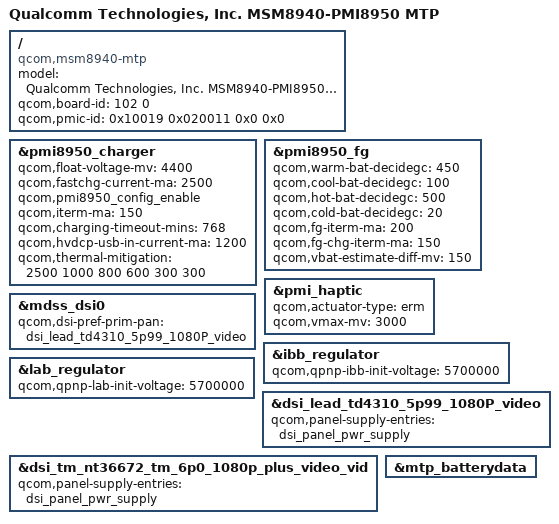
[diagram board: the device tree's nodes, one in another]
/*
 * Copyright (c) 2016, The Linux Foundation. All rights reserved.
 *
 * This program is free software; you can redistribute it and/or modify
 * it under the terms of the GNU General Public License version 2 and
 * only version 2 as published by the Free Software Foundation.
 *
 * This program is distributed in the hope that it will be useful,
 * but WITHOUT ANY WARRANTY; without even the implied warranty of
 * MERCHANTABILITY or FITNESS FOR A PARTICULAR PURPOSE.  See the
 * GNU General Public License for more details.
 */

/dts-v1/;

#include "msm8940.dtsi"
#include "msm8940-pmi8950-mtp.dtsi"
#include "zte-msm8940-pmi8950-maxxl2.dtsi"
#include "touch-key-backlight-maxx12.dtsi"
#include "msm8940-camera-sensor-zte-maxxl2.dtsi"

#include "dsi-panel-zte-lead-td4310-5p99-1080p-video.dtsi"
#include "dsi-panel-zte-tm-nt36672-tm-6p0-1080p-plus-video.dtsi"
/ {
	model = "Qualcomm Technologies, Inc. MSM8940-PMI8950 MTP";
	compatible = "qcom,msm8940-mtp", "qcom,msm8940", "qcom,mtp";
	qcom,board-id= <102 0>;
	qcom,pmic-id = <0x10019 0x020011 0x0 0x0>;
};

&pmi8950_charger {
	qcom,float-voltage-mv = <4400>;
	qcom,fastchg-current-ma = <2500>;
	qcom,pmi8950_config_enable;
	qcom,iterm-ma = <150>;
	qcom,charging-timeout-mins = <768>;
	qcom,hvdcp-usb-in-current-ma = <1200>;
	qcom,thermal-mitigation = <2500 1000 800 600 300 300>;
};
&pmi8950_fg{
	qcom,warm-bat-decidegc = <450>;
	qcom,cool-bat-decidegc = <100>;
	qcom,hot-bat-decidegc = <500>;
	qcom,cold-bat-decidegc = <20>;
	qcom,fg-iterm-ma = <200>;
	qcom,fg-chg-iterm-ma = <150>;
	qcom,vbat-estimate-diff-mv = <150>;
};
&pmi_haptic{
	qcom,actuator-type = "erm";
	qcom,vmax-mv = <3000>;
};
&mdss_dsi0 {
	qcom,dsi-pref-prim-pan = <&dsi_lead_td4310_5p99_1080P_video>;
};

&ibb_regulator {
	qcom,qpnp-ibb-init-voltage = <5700000>;
};

&lab_regulator {
	qcom,qpnp-lab-init-voltage = <5700000>;
};

&dsi_lead_td4310_5p99_1080P_video {
	qcom,panel-supply-entries = <&dsi_panel_pwr_supply>;
};

&dsi_tm_nt36672_tm_6p0_1080p_plus_video_vid {
	qcom,panel-supply-entries = <&dsi_panel_pwr_supply>;
};

&mtp_batterydata {
	/delete-node/qcom,2685302_zte_p8f0v70_3000mah_averaged_masterslave_nov22nd2016;
	#include "zte_z6410s_3900mah.dtsi"
};
